# GD32M53x register map
File version: 1.0
CPU: CM33 r2p1, little endian, MPU, FPU, DSP, 4 interrupt priority bits
Registers are 32-bit, read-write, reset 0x0 unless marked. A register's access mark holds for its fields unless they carry their own. Offsets are from the block's base; [hi:lo] are bit positions; {n}, {i} and the like mark numbered series.

## TIMER0 — Advanced timer
Base 0x40012C00
Same registers: TIMER7 0x40013400
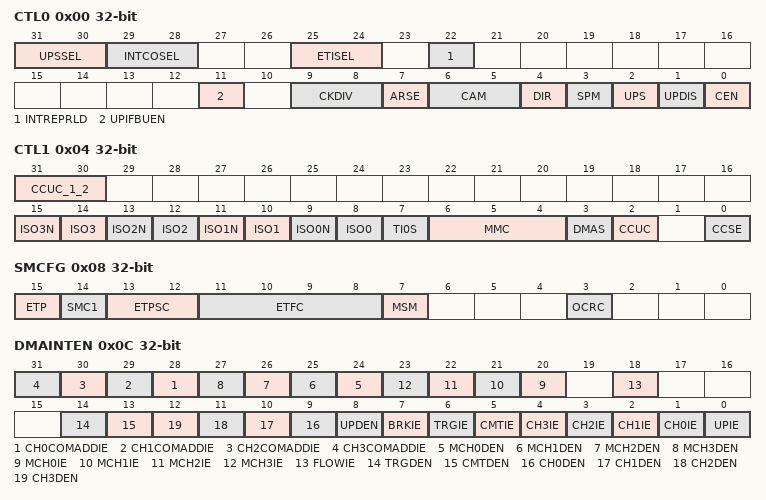
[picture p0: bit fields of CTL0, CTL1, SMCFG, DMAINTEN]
0x00 CTL0 — Control register 0
  [31:30] UPSSEL — update repeat counter overflow source selection, set when the update repeat counter decrement
  [29:28] INTCOSEL — interrupt repeat counter overflow source selection, set when interrupt repeat counter decrement
  [25:24] ETISEL — timer external trigger input signal select
  [22] INTREPRLD — interrupt repeat counter immediate reload
  [11] UPIFBUEN — upif bit backup enable
  [9:8] CKDIV — clock division
  [7] ARSE — auto-reload shadow enable
  [6:5] CAM — counter align mode selection
  [4] DIR — direction
  [3] SPM — single pulse mode
  [2] UPS — update source
  [1] UPDIS — update disable
  [0] CEN — counter enable
0x04 CTL1 — Control register 1
  [31:30] CCUC_1_2 — commutation control shadow register update control
  [2n+9] ISO{n}N (n=0..3) — idle state of multi mode channel {n} complementary output
  [2n+8] ISO{n} (n=0..3) — idle state of channel {n} output
  [7] TI0S — channel 0 trigger input selection
  [6:4] MMC — master mode control
  [3] DMAS — dma request source selection
  [2] CCUC — commutation control shadow register update control
  [0] CCSE — commutation control shadow enable
0x08 SMCFG — Slave mode configuration register
  [15] ETP — external trigger polarity
  [14] SMC1 — part of slave mode controller is used to enable external clock mode 1
  [13:12] ETPSC — external trigger prescaler
  [11:8] ETFC — external trigger filter control
  [7] MSM — master-slave mode
  [3] OCRC — oxcpre/ moxcpre clear source selection
0x0C DMAINTEN — DMA and interrupt enable register
  [n+28] CH{n}COMADDIE (n=0..3) — channel {n} additional compare interrupt enable
  [n+24] MCH{n}DEN (n=0..3) — multi mode channel {n} capture/compare dma request enable
  [n+20] MCH{n}IE (n=0..3) — multi mode channel {n} capture/compare interrupt enable
  [18] FLOWIE — overflow or underflow interrupt enable
  [14] TRGDEN — trigger dma request enable
  [13] CMTDEN — commutation dma request enable
  [n+9] CH{n}DEN (n=0..3) — channel {n} capture/compare dma request enable
  [8] UPDEN — update dma request enable
  [7] BRKIE — break interrupt enable
  [6] TRGIE — trigger interrupt enable
  [5] CMTIE — commutation interrupt enable
  [n+1] CH{n}IE (n=0..3) — channel {n} capture/compare interrupt enable
  [0] UPIE — update interrupt enable
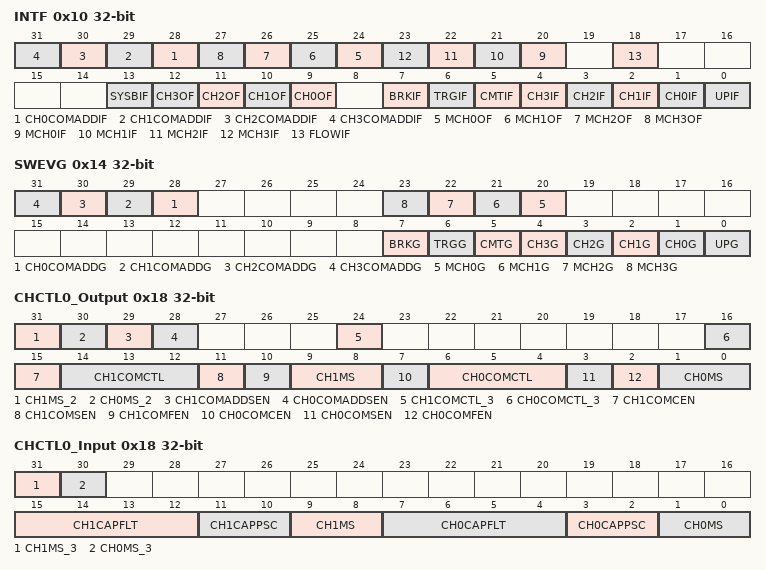
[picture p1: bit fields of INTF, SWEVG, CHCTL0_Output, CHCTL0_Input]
0x10 INTF — Interrupt flag register
  [n+28] CH{n}COMADDIF (n=0..3) — channel {n} additional compare interrupt flag
  [n+24] MCH{n}OF (n=0..3) — multi mode channel {n} over capture flag
  [n+20] MCH{n}IF (n=0..3) — multi mode channel {n} capture/compare interrupt flag
  [18] FLOWIF — underflow interrupt flag
  [13] SYSBIF — system source break interrupt flag
  [n+9] CH{n}OF (n=0..3) — channel {n} over capture flag
  [7] BRKIF — break interrupt flag
  [6] TRGIF — trigger interrupt flag
  [5] CMTIF — channel commutation interrupt flag
  [n+1] CH{n}IF (n=0..3) — channel {n} capture/compare interrupt flag
  [0] UPIF — update interrupt flag
0x14 SWEVG wo — Software event generation register
  [n+28] CH{n}COMADDG (n=0..3) — channel {n} additional compare event generation
  [n+20] MCH{n}G (n=0..3) — multi mode channel {n} capture or compare event generation
  [7] BRKG — break event generation
  [6] TRGG — trigger event generation
  [5] CMTG — channel commutation event generation
  [n+1] CH{n}G (n=0..3) — channel {n} capture or compare event generation
  [0] UPG — update event generation
0x18 CHCTL0_Output — Channel control register 0 (output mode)
  [31] CH1MS_2 — channel 1 i/o mode selection
  [30] CH0MS_2 — channel 0 i/o mode selection
  [29] CH1COMADDSEN — channel 1 additional compare output shadow enable
  [28] CH0COMADDSEN — channel 0 additional compare output shadow enable
  [24] CH1COMCTL_3 — channel 1 compare output control
  [16] CH0COMCTL_3 — channel 0 compare output control
  [15] CH1COMCEN — channel 1 output compare clear enable
  [14:12] CH1COMCTL — channel 1 compare output control
  [11] CH1COMSEN — channel 1 output compare shadow enable
  [10] CH1COMFEN — channel 1 output compare fast enable
  [9:8] CH1MS — channel 1 mode selection
  [7] CH0COMCEN — channel 0 output compare clear enable
  [6:4] CH0COMCTL — channel 0 compare output control
  [3] CH0COMSEN — channel 0 compare output shadow enable
  [2] CH0COMFEN — channel 0 output compare fast enable
  [1:0] CH0MS — channel 0 i/o mode selection
0x18 CHCTL0_Input (alternate view of CHCTL0_Output) — Channel control register 0 (input mode)
  [31] CH1MS_3 — Channel 1 I/O mode selection
  [30] CH0MS_3 — Channel 0 I/O mode selection
  [15:12] CH1CAPFLT — Channel 1 input capture filter control
  [11:10] CH1CAPPSC — Channel 1 input capture prescaler
  [9:8] CH1MS — Channel 1 mode selection
  [7:4] CH0CAPFLT — Channel 0 input capture filter control
  [3:2] CH0CAPPSC — Channel 0 input capture prescaler
  [1:0] CH0MS — Channel 0 I/O mode selection
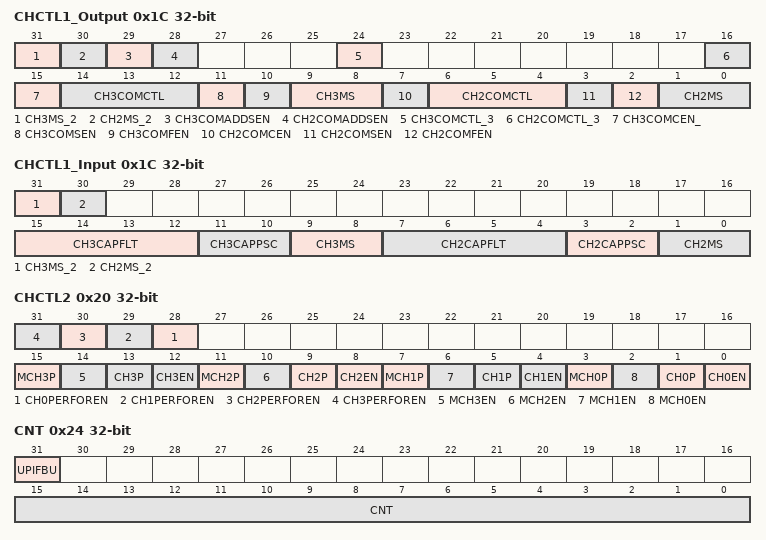
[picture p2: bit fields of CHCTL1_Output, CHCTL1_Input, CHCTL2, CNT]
0x1C CHCTL1_Output — Channel control register 1 (output mode)
  [31] CH3MS_2 — channel 3 i/o mode selection
  [30] CH2MS_2 — channel 2 i/o mode selection
  [29] CH3COMADDSEN — channel 3 additional compare output shadow enable
  [28] CH2COMADDSEN — channel 2 additional compare output shadow enable
  [24] CH3COMCTL_3 — channel 3 compare output control
  [16] CH2COMCTL_3 — channel 2 compare output control
  [15] CH3COMCEN_ — channel 3 output compare clear enable
  [14:12] CH3COMCTL — channel 3 compare output control
  [11] CH3COMSEN — channel 3 output compare shadow enable
  [10] CH3COMFEN — channel 3 output compare fast enable
  [9:8] CH3MS — channel 3 i/o mode selection
  [7] CH2COMCEN — channel 2 output compare clear enable
  [6:4] CH2COMCTL — channel 2 compare output control
  [3] CH2COMSEN — channel 2 compare output shadow enable
  [2] CH2COMFEN — channel 2 output compare fast enable
  [1:0] CH2MS — channel 2 i/o mode selection
0x1C CHCTL1_Input (alternate view of CHCTL1_Output) — Channel control register 1 (input mode)
  [31] CH3MS_2 — Channel 3 I/O mode selection
  [30] CH2MS_2 — Channel 2 I/O mode selection
  [15:12] CH3CAPFLT — Channel 3 input capture filter control
  [11:10] CH3CAPPSC — Channel 3 input capture prescaler
  [9:8] CH3MS — Channel 3 mode selection
  [7:4] CH2CAPFLT — Channel 2 input capture filter control
  [3:2] CH2CAPPSC — Channel 2 input capture prescaler
  [1:0] CH2MS — Channel 2 I/O mode selection
0x20 CHCTL2 — Channel control register 2
  [n+28] CH{n}PERFOREN (n=0..3) — Channel {n} in the composite PWM or asymmetric PWM mode, the period point match moment O{n}CPRE level setting
  [15] MCH3P — multi mode channel 3 capture/compare polarity
  [14] MCH3EN — multi mode channel 3 capture/compare enable
  [4n+1] CH{n}P (n=0..3) — channel {n} capture/compare polarity
  [4n] CH{n}EN (n=0..3) — channel {n} capture/compare enable
  [11] MCH2P — multi mode channel 2 output polarity
  [10] MCH2EN — multi mode channel 2 output enable
  [7] MCH1P — multi mode channel 1 output polarity
  [6] MCH1EN — multi mode channel 1 output enable
  [3] MCH0P — multi mode channel 0 output polarity
  [2] MCH0EN — multi mode channel 0 capture/compare enable
0x24 CNT access per field — Counter register
  [31] UPIFBU ro — upif bit backup
  [15:0] CNT rw — this bit-field indicates the current counter value
0x28 PSC — Prescaler register
  [15:0] PSC — prescaler value of the counter clock
0x2C CAR reset 0xFFFF — Counter auto reload register
  [15:0] CARL — counter auto reload value
0x30 CREP — Counter repetition register
  [7:0] CREP — counter repetition value
{0x34+4i} CH{i}CV (i=0..3) — Channel {i} capture/compare value register
  [15:0] CH{i}VAL — capture/compare value of channel {i}
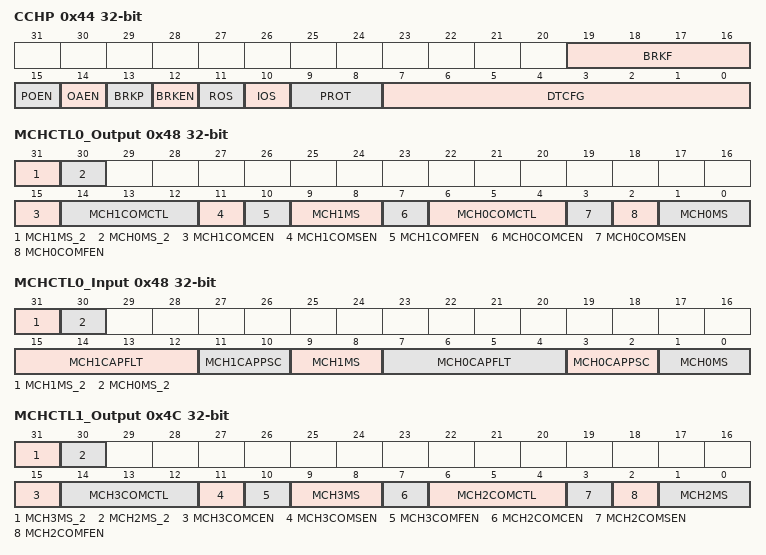
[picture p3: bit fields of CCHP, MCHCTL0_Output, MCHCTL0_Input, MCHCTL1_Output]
0x44 CCHP — Complementary channel protection register
  [19:16] BRKF — break input signal filter
  [15] POEN — primary output enable
  [14] OAEN — output automatic enable
  [13] BRKP — break input signal polarity
  [12] BRKEN — break input signal enable
  [11] ROS — run mode off-state enable
  [10] IOS — idle mode off-state enable
  [9:8] PROT — complementary register protect control
  [7:0] DTCFG — dead time configuration
0x48 MCHCTL0_Output — Multi mode channel control register 0 (output mode)
  [31] MCH1MS_2 — multi mode channel 1 i/o mode selection
  [30] MCH0MS_2 — multi mode channel 0 i/o mode selection
  [15] MCH1COMCEN — multi mode channel 1 output compare clear enable
  [14:12] MCH1COMCTL — multi mode channel 1 compare output control
  [11] MCH1COMSEN — multi mode channel 1 output compare shadow enable
  [10] MCH1COMFEN — multi mode channel 1 output compare fast enable
  [9:8] MCH1MS — multi mode channel 1 i/o mode selection
  [7] MCH0COMCEN — multi mode channel 0 output compare clear enable
  [6:4] MCH0COMCTL — multi mode channel 0 output compare control
  [3] MCH0COMSEN — multi mode channel 0 output compare shadow enable
  [2] MCH0COMFEN — multi mode channel 0 output compare fast enable
  [1:0] MCH0MS — multi mode channel 0 i/o mode selection
0x48 MCHCTL0_Input (alternate view of MCHCTL0_Output) — Multi mode channel control register 0 (input mode)
  [31] MCH1MS_2 — Multi mode channel 1 I/O mode selection
  [30] MCH0MS_2 — Multi mode channel 0 I/O mode selection
  [15:12] MCH1CAPFLT — Multi mode channel 1 input capture filter control
  [11:10] MCH1CAPPSC — Multi mode channel 1 input capture prescaler
  [9:8] MCH1MS — Multi mode channel 1 I/O mode selection
  [7:4] MCH0CAPFLT — Multi mode channel 0 input capture filter control
  [3:2] MCH0CAPPSC — Multi mode channel 0 input capture prescaler
  [1:0] MCH0MS — Multi mode channel 0 I/O mode selection
0x4C MCHCTL1_Output — Multi mode channel control register 1 (output mode)
  [31] MCH3MS_2 — multi mode channel 1 i/o mode selection
  [30] MCH2MS_2 — multi mode channel 0 i/o mode selection
  [15] MCH3COMCEN — multi mode channel 3 output compare clear enable
  [14:12] MCH3COMCTL — multi mode channel 3 compare output control
  [11] MCH3COMSEN — multi mode channel 3 output compare shadow enable
  [10] MCH3COMFEN — multi mode channel 3 output compare fast enable
  [9:8] MCH3MS — multi mode channel 3 i/o mode selection
  [7] MCH2COMCEN — multi mode channel 2 output compare clear enable
  [6:4] MCH2COMCTL — multi mode channel 2 compare output control
  [3] MCH2COMSEN — multi mode channel 2 output compare shadow enable
  [2] MCH2COMFEN — multi mode channel 2 output compare fast enable
  [1:0] MCH2MS — multi mode channel 2 i/o mode selection
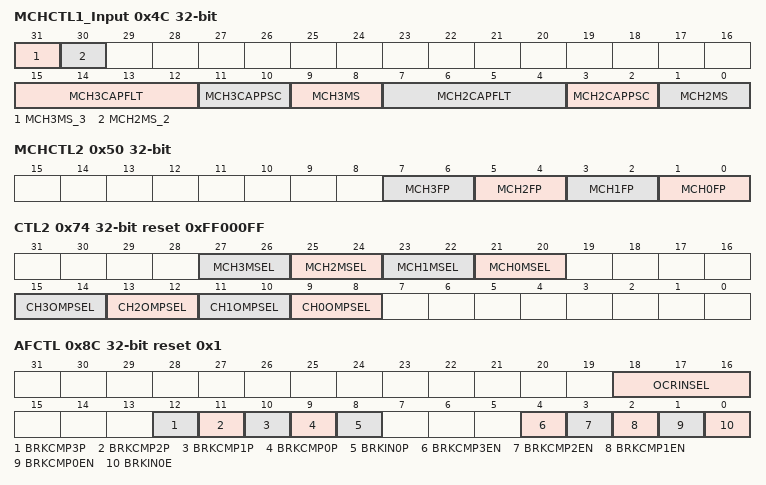
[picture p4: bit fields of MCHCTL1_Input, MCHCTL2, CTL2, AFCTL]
0x4C MCHCTL1_Input (alternate view of MCHCTL1_Output) — Multi mode channel control register 1 (input mode)
  [31] MCH3MS_3 — Multi mode channel 1 I/O mode selection
  [30] MCH2MS_2 — Multi mode channel 0 I/O mode selection
  [15:12] MCH3CAPFLT — Multi mode channel 3 input capture filter control
  [11:10] MCH3CAPPSC — Multi mode channel 3 input capture prescaler
  [9:8] MCH3MS — Multi mode channel 3 I/O mode selection
  [7:4] MCH2CAPFLT — Multi mode channel 2 input capture filter control
  [3:2] MCH2CAPPSC — Multi mode channel 2 input capture prescaler
  [1:0] MCH2MS — Multi mode channel 2 I/O mode selection
0x50 MCHCTL2 — Multi mode channel control register 2
  [2n+1:2n] MCH{n}FP (n=0..3) — multi mode channel {n} capture/compare free polarity
{0x54+4i} MCH{i}CV (i=0..2) — Multi mode channel {i} capture/compare value register
  [15:0] MCH{i}VAL — capture/compare value of multi mode channel {i}
0x60 MCH3CV — Multi mode channel 3 capture/compare value register
  [15:0] MCH3VAL — capture/compare value of channel 3
{0x64+4i} CH{i}COMV_ADD (i=0..3) — Channel {i} additional compare value register
  [15:0] CH{i}COMVAL_ADD — additional compare value of channel {i}
0x74 CTL2 reset 0xFF000FF — Control register 2
  [2n+21:2n+20] MCH{n}MSEL (n=0..3) — multi mode channel {n} mode select
  [2n+9:2n+8] CH{n}OMPSEL (n=0..3) — channel {n} output match pulse select
0x8C AFCTL reset 0x1 — Alternate function control register
  [18:16] OCRINSEL — ocpre_clr inputs selection
  [12] BRKCMP3P — break cmp3 input polarity, reference to brkcmp0p
  [11] BRKCMP2P — break cmp2 input polarity, reference to brkcmp0p
  [10] BRKCMP1P — break cmp1 input polarity, reference to brkcmp0p
  [9] BRKCMP0P — this bit specifies the polarity of the cmp0 input signal
  [8] BRKIN0P — brkin0 input signal polarity
  [4] BRKCMP3EN — break cmp3 enable, reference to brkcmp0en
  [3] BRKCMP2EN — break cmp2 enable, reference to brkcmp0en
  [2] BRKCMP1EN — break cmp1 enable, reference to brkcmp0en
  [1] BRKCMP0EN — break cmp0 enable
  [0] BRKIN0E — brkin0 input signal enable
0x90 IREP — Interrupt Counter repetition register
  [7:0] IREP — interrupt counter repetition value
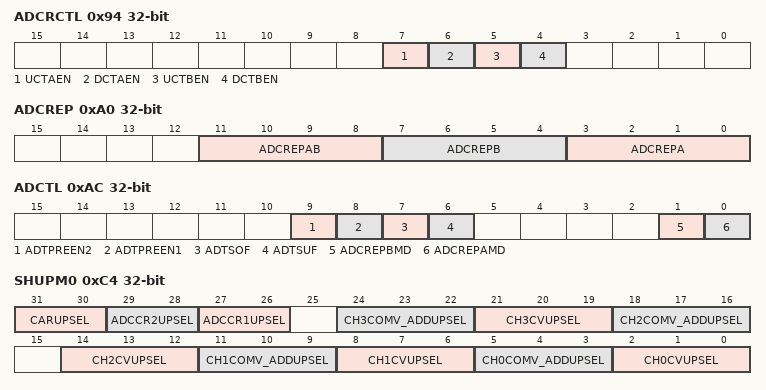
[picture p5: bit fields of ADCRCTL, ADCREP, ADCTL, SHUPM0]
0x94 ADCRCTL — ADC conversion request control register
  [7] UCTAEN — the cnt up-count timerx_trga enable
  [6] DCTAEN — the cnt down-count timerx_trga enable
  [5] UCTBEN — the cnt up-count timerx_trgb enable
  [4] DCTBEN — the cnt down-count timerx_trgb enable
0x98 ADCCR1 — ADC trigger compare value register1
  [15:0] ADTCV1 — the adc trigger compare value 1
0x9C ADCCR2 — ADC trigger compare value register2
  [15:0] ADTCV2 — the adc trigger compare value 2
0xA0 ADCREP — ADC counter repetition register
  [11:8] ADCREPAB — adc timerx_trgab repeat count setting
  [7:4] ADCREPB — adc timerx_trgb repeat count setting
  [3:0] ADCREPA — adc timerx_trga repeat count setting
0xAC ADCTL — ADC trigger control register
  [9] ADTPREEN2 — adc repeat count reload immediately
  [8] ADTPREEN1 — must be kept at reset value
  [7] ADTSOF — adtcv2[15:0] preload enable
  [6] ADTSUF — adtcv1[15:0] preload enable
  [1] ADCREPBMD — adc trigger signal timerx_trguf enable when timerx_cnt underflow
  [0] ADCREPAMD — must be kept at reset value
0xC4 SHUPM0 — Shadow update mode register 0
  [31:30] CARUPSEL — the counter auto reload value update mode selection, used to set when the counter auto reload value will be automatically overloaded
  [29:28] ADCCR2UPSEL — the adc triggered comparison value 2 update mode selection
  [27:26] ADCCR1UPSEL — the adc triggered comparison value 1 update mode selection, used to set when the adc triggered comparison value is automatically overloaded
  [24:22] CH3COMV_ADDUPSEL — channel 3 additional comparison value update mode selection
  [21:19] CH3CVUPSEL — channel 3 capture/compare value update mode selection
  [18:16] CH2COMV_ADDUPSEL — channel 2 additional comparison value update mode selection
  [14:12] CH2CVUPSEL — channel 2 capture/compare value update mode selection
  [11:9] CH1COMV_ADDUPSEL — channel 1 additional comparison value update mode selection
  [8:6] CH1CVUPSEL — channel 1 capture/compare value update mode selection
  [5:3] CH0COMV_ADDUPSEL — channel 0 additional comparison value update mode selection, used to set when additional comparison values are automatically overloaded
  [2:0] CH0CVUPSEL — channel 0 capture/compare value update mode selection, used to set when the compare value is automatically overloaded
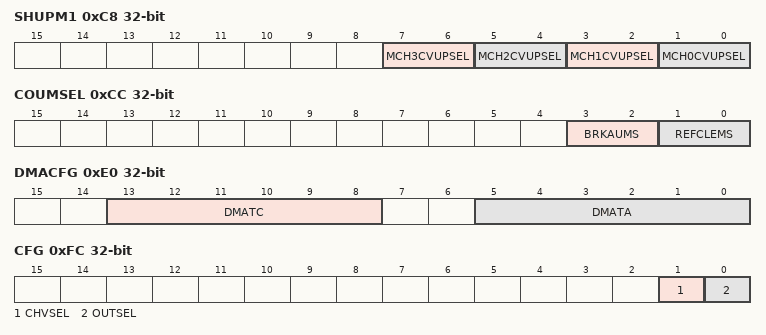
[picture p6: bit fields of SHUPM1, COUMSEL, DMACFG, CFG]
0xC8 SHUPM1 — Shadow update mode register 1
  [7:6] MCH3CVUPSEL — multi mode channel 3 capture/compare value update mode selection
  [5:4] MCH2CVUPSEL — multi mode channel 2 capture/compare value update mode selection
  [3:2] MCH1CVUPSEL — multi mode channel 1 capture/compare value update mode selection
  [1:0] MCH0CVUPSEL — multi mode channel 0 capture/compare value update mode selection, used to set when the compare value is automatically overloaded
0xCC COUMSEL — Counter overflow or underflow mode selection register
  [3:2] BRKAUMS — break automatic output function mode selection
  [1:0] REFCLEMS — reference signal output clear signal mode selection, when the hardware sets the reference signal output clear signal is invalid
0xE0 DMACFG — DMA configuration register
  [13:8] DMATC — dma transfer count
  [5:0] DMATA — dma transfer access start address
0xE4 DMATB — DMA transfer buffer register
  [31:0] DMATB — dma transfer buffer
0xFC CFG — Configuration register
  [1] CHVSEL — write chxval register selection bit
  [0] OUTSEL — the output value selection bit
